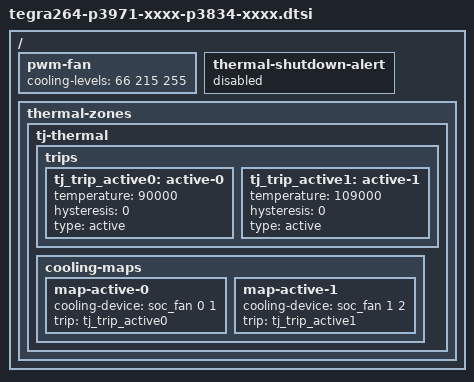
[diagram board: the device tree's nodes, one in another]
// SPDX-License-Identifier: GPL-2.0-only
// SPDX-FileCopyrightText: Copyright (c) 2024-2025, NVIDIA CORPORATION & AFFILIATES.  All rights reserved.

/ {
	pwm-fan {
		cooling-levels = <66 215 255>;
	};

	thermal-shutdown-alert {
		status = "disabled";
	};

	thermal-zones {
		tj-thermal {
			trips {
				tj_trip_active0: active-0 {
					temperature = <90000>;
					hysteresis = <0>;
					type = "active";
				};

				tj_trip_active1: active-1 {
					temperature = <109000>;
					hysteresis = <0>;
					type = "active";
				};
			};

			cooling-maps {
				map-active-0 {
					cooling-device = <&soc_fan 0 1>;
					trip = <&tj_trip_active0>;
				};

				map-active-1 {
					cooling-device = <&soc_fan 1 2>;
					trip = <&tj_trip_active1>;
				};
			};
		};
	};
};
